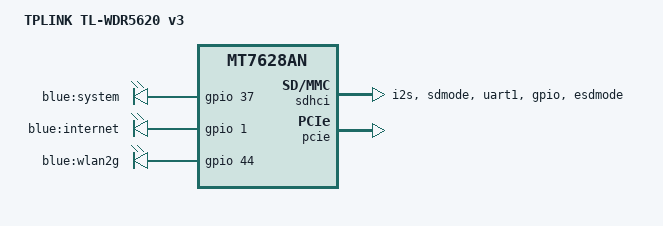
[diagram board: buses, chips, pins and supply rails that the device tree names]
#include "mt7628an_hiwifi_hc5x61a.dtsi"

/ {
	compatible = "tplink,tl-wdr5620-v3", "mediatek,mt7628an-soc";
	model = "TPLINK TL-WDR5620 v3";

	leds {
		compatible = "gpio-leds";

		led_system: system {
			label = "blue:system";
			gpios = <&gpio 37 GPIO_ACTIVE_HIGH>;
		};

		internet {
			label = "blue:internet";
			gpios = <&gpio 1 GPIO_ACTIVE_HIGH>;
		};

		wlan2g {
			label = "blue:wlan2g";
			gpios = <&gpio 44 GPIO_ACTIVE_HIGH>;
			linux,default-trigger = "phy0tpt";
		};
	};
};

&pinctrl {
	sdxc_router_pins: sdxc_router_mode {
		gpio {
			groups = "i2s", "sdmode", "uart1", "gpio";
			function= "gpio";
		};

		esdmode {
			groups = "esdmode";
			function= "sdxc";
		};
	};

	state_default: pinctrl0 {
		gpio {
			groups = "i2c", "refclk", "wdt", "wled_an";
			function= "gpio";
		};
	};
};

&sdhci {
	status = "okay";
	pinctrl-0 = <&sdxc_router_pins>;
};

&ehci {
	status = "disabled";
};

&ohci {
	status = "disabled";
};

&pcie {
	status = "okay";
};

&pcie0 {
	wifi@0,0 {
		reg = <0x0000 0 0 0 0>;
		mediatek,mtd-eeprom = <&factory 0x8000>;
		nvmem-cells = <&macaddr_factory_2e>;
		nvmem-cell-names = "mac-address";
		ieee80211-freq-limit = <5000000 6000000>;

		led {
			led-sources = <2>;
			led-active-low;
		};
	};
};

&factory {
	compatible = "nvmem-cells";
	#address-cells = <1>;
	#size-cells = <1>;

	macaddr_factory_2e: macaddr@2e {
		reg = <0x2e 0x6>;
	};
};
